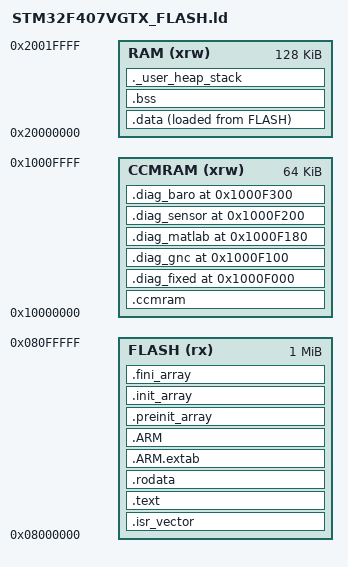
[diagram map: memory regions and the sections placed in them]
/*
******************************************************************************
**
** @file        : LinkerScript.ld
**
** @author      : Auto-generated by STM32CubeIDE
**
**  Abstract    : Linker script for STM32F407G-DISC1 Board embedding STM32F407VGTx Device from stm32f4 series
**                      1024KBytes FLASH
**                      64KBytes CCMRAM
**                      128KBytes RAM
**
**                Set heap size, stack size and stack location according
**                to application requirements.
**
**                Set memory bank area and size if external memory is used
**
**  Target      : STMicroelectronics STM32
**
**  Distribution: The file is distributed as is, without any warranty
**                of any kind.
**
******************************************************************************
** @attention
**
** Copyright (c) 2026 STMicroelectronics.
** All rights reserved.
**
** This software is licensed under terms that can be found in the LICENSE file
** in the root directory of this software component.
** If no LICENSE file comes with this software, it is provided AS-IS.
**
******************************************************************************
*/

/* Entry Point */
ENTRY(Reset_Handler)

/* Highest address of the user mode stack */
_estack = ORIGIN(RAM) + LENGTH(RAM); /* end of "RAM" Ram type memory */

_Min_Heap_Size = 0x200; /* required amount of heap */
_Min_Stack_Size = 0x400; /* required amount of stack */

/* Memories definition */
MEMORY
{
  CCMRAM    (xrw)    : ORIGIN = 0x10000000,   LENGTH = 64K
  RAM    (xrw)    : ORIGIN = 0x20000000,   LENGTH = 128K
  FLASH    (rx)    : ORIGIN = 0x8000000,   LENGTH = 1024K
}

/* Sections */
SECTIONS
{
  /* The startup code into "FLASH" Rom type memory */
  .isr_vector :
  {
    . = ALIGN(4);
    KEEP(*(.isr_vector)) /* Startup code */
    . = ALIGN(4);
  } >FLASH

  /* The program code and other data into "FLASH" Rom type memory */
  .text :
  {
    . = ALIGN(4);
    *(.text)           /* .text sections (code) */
    *(.text*)          /* .text* sections (code) */
    *(.glue_7)         /* glue arm to thumb code */
    *(.glue_7t)        /* glue thumb to arm code */
    *(.eh_frame)

    KEEP (*(.init))
    KEEP (*(.fini))

    . = ALIGN(4);
    _etext = .;        /* define a global symbols at end of code */
  } >FLASH

  /* Constant data into "FLASH" Rom type memory */
  .rodata :
  {
    . = ALIGN(4);
    *(.rodata)         /* .rodata sections (constants, strings, etc.) */
    *(.rodata*)        /* .rodata* sections (constants, strings, etc.) */
    . = ALIGN(4);
  } >FLASH

  .ARM.extab (READONLY) : /* The "READONLY" keyword is only supported in GCC11 and later, remove it if using GCC10 or earlier. */
  {
    . = ALIGN(4);
    *(.ARM.extab* .gnu.linkonce.armextab.*)
    . = ALIGN(4);
  } >FLASH

  .ARM (READONLY) : /* The "READONLY" keyword is only supported in GCC11 and later, remove it if using GCC10 or earlier. */
  {
    . = ALIGN(4);
    __exidx_start = .;
    *(.ARM.exidx*)
    __exidx_end = .;
    . = ALIGN(4);
  } >FLASH

  .preinit_array (READONLY) : /* The "READONLY" keyword is only supported in GCC11 and later, remove it if using GCC10 or earlier. */
  {
    . = ALIGN(4);
    PROVIDE_HIDDEN (__preinit_array_start = .);
    KEEP (*(.preinit_array*))
    PROVIDE_HIDDEN (__preinit_array_end = .);
    . = ALIGN(4);
  } >FLASH

  .init_array (READONLY) : /* The "READONLY" keyword is only supported in GCC11 and later, remove it if using GCC10 or earlier. */
  {
    . = ALIGN(4);
    PROVIDE_HIDDEN (__init_array_start = .);
    KEEP (*(SORT(.init_array.*)))
    KEEP (*(.init_array*))
    PROVIDE_HIDDEN (__init_array_end = .);
    . = ALIGN(4);
  } >FLASH

  .fini_array (READONLY) : /* The "READONLY" keyword is only supported in GCC11 and later, remove it if using GCC10 or earlier. */
  {
    . = ALIGN(4);
    PROVIDE_HIDDEN (__fini_array_start = .);
    KEEP (*(SORT(.fini_array.*)))
    KEEP (*(.fini_array*))
    PROVIDE_HIDDEN (__fini_array_end = .);
    . = ALIGN(4);
  } >FLASH

  /* Used by the startup to initialize data */
  _sidata = LOADADDR(.data);

  /* Initialized data sections into "RAM" Ram type memory */
  .data :
  {
    . = ALIGN(4);
    _sdata = .;        /* create a global symbol at data start */
    *(.data)           /* .data sections */
    *(.data*)          /* .data* sections */
    *(.RamFunc)        /* .RamFunc sections */
    *(.RamFunc*)       /* .RamFunc* sections */

    . = ALIGN(4);
    _edata = .;        /* define a global symbol at data end */

  } >RAM AT> FLASH

  _siccmram = LOADADDR(.ccmram);

  /* CCM-RAM section
  *
  * IMPORTANT NOTE!
  * If initialized variables will be placed in this section,
  * the startup code needs to be modified to copy the init-values.
  */
  .ccmram (NOLOAD) :
  {
    . = ALIGN(4);
    _sccmram = .;       /* create a global symbol at ccmram start */
    *(.ccmram)
    *(.ccmram*)

    . = ALIGN(4);
    _eccmram = .;       /* create a global symbol at ccmram end */
  } >CCMRAM

  /*
   * V8.15D fixed diagnostic window.
   *
   * Read this block by RAW ADDRESS in CubeIDE Memory view:
   *     0x1000F000
   *
   * This bypasses DWARF/Live Expressions symbol decoding completely.
   */
  .diag_fixed 0x1000F000 (NOLOAD) :
  {
    . = ALIGN(4);
    KEEP(*(.diag_fixed))
    . = ALIGN(4);
  } >CCMRAM

  ASSERT(_eccmram <= 0x1000F000,
         "CCMRAM data overlaps V8.15D fixed diagnostic window")
  ASSERT(SIZEOF(.diag_fixed) <= 0x100,
         "V8.15D base diagnostic block exceeds first 256 bytes")

  /*
   * V8.16 GNC fixed diagnostic block.
   * Raw address: 0x1000F100
   */
  .diag_gnc 0x1000F100 (NOLOAD) :
  {
    . = ALIGN(4);
    KEEP(*(.diag_gnc))
    . = ALIGN(4);
  } >CCMRAM

  ASSERT(SIZEOF(.diag_gnc) <= 0x80,
         "V8.16 GNC diagnostic block exceeds first 128 bytes")

  .diag_matlab 0x1000F180 (NOLOAD) :
  {
    . = ALIGN(4);
    KEEP(*(.diag_matlab))
    . = ALIGN(4);
  } >CCMRAM

  ASSERT(SIZEOF(.diag_matlab) <= 0x80,
         "V8.17 MATLAB port diagnostic block exceeds 128 bytes")

  /* V8.18 sensor qualification raw block: 0x1000F200..0x1000F2FF */
  .diag_sensor 0x1000F200 (NOLOAD) :
  {
    . = ALIGN(4);
    KEEP(*(.diag_sensor))
    . = ALIGN(4);
  } >CCMRAM

  ASSERT(SIZEOF(.diag_sensor) <= 0x100,
         "V8.18 sensor diagnostic block exceeds 256 bytes")

  /* V8.19E BMP585 200 Hz direct-read diagnostic: 0x1000F300..0x1000F3FF */
  .diag_baro 0x1000F300 (NOLOAD) :
  {
    . = ALIGN(4);
    KEEP(*(.diag_baro))
    . = ALIGN(4);
  } >CCMRAM

  ASSERT(SIZEOF(.diag_baro) <= 0x100,
         "V8.19E barometer diagnostic block exceeds 256 bytes")

  /* Uninitialized data section into "RAM" Ram type memory */
  . = ALIGN(4);
  .bss :
  {
    /* This is used by the startup in order to initialize the .bss section */
    _sbss = .;         /* define a global symbol at bss start */
    __bss_start__ = _sbss;
    *(.bss)
    *(.bss*)
    *(COMMON)

    . = ALIGN(4);
    _ebss = .;         /* define a global symbol at bss end */
    __bss_end__ = _ebss;
  } >RAM

  /* User_heap_stack section, used to check that there is enough "RAM" Ram  type memory left */
  ._user_heap_stack :
  {
    . = ALIGN(8);
    PROVIDE ( end = . );
    PROVIDE ( _end = . );
    . = . + _Min_Heap_Size;
    . = . + _Min_Stack_Size;
    . = ALIGN(8);
  } >RAM

  /* Remove information from the compiler libraries */
  /DISCARD/ :
  {
    libc.a ( * )
    libm.a ( * )
    libgcc.a ( * )
  }

  .ARM.attributes 0 : { *(.ARM.attributes) }
}
